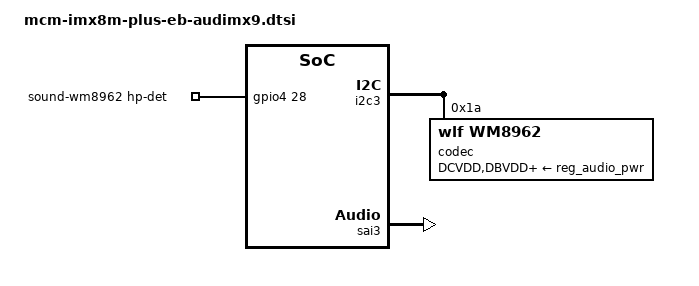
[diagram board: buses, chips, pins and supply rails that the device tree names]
&{/} {
	sound-wm8962 {
		compatible = "fsl,imx-audio-wm8962x";
		model = "wm8962-audio";
		audio-cpu = <&sai3>;
		audio-codec = <&codec>;
		hp-det-gpio = <&gpio4 28 0>;
		audio-routing =
			"Headphone Jack", "HPOUTL",
			"Headphone Jack", "HPOUTR",
			"Ext Spk", "SPKOUTL",
			"Ext Spk", "SPKOUTR",
			"AMIC", "MICBIAS",
			"IN1L", "AMIC",
			"IN1R", "AMIC";
	};
};

&i2c3 {
	#address-cells = <1>;
	#size-cells = <0>;
	status = "okay";

	codec: wm8962@1a {
		compatible = "wlf,wm8962";
		reg = <0x1a>;
		clocks = <&audio_blk_ctrl IMX8MP_CLK_AUDIOMIX_SAI3_MCLK1>;
		DCVDD-supply = <&reg_audio_pwr>;
		DBVDD-supply = <&reg_audio_pwr>;
		AVDD-supply = <&reg_audio_pwr>;
		CPVDD-supply = <&reg_audio_pwr>;
		MICVDD-supply = <&reg_audio_pwr>;
		PLLVDD-supply = <&reg_audio_pwr>;
		SPKVDD1-supply = <&reg_audio_pwr>;
		SPKVDD2-supply = <&reg_audio_pwr>;
		gpio-cfg = <
			0x0000 /* 0:Default */
			0x0000 /* 1:Default */
			0x0000 /* 2:FN_DMICCLK */
			0x0000 /* 3:Default */
			0x0000 /* 4:FN_DMICCDAT */
			0x0000 /* 5:Default */
		>;
		status = "okay";
	};
};

&sai3 {
	#sound-dai-cells = <0>;
	pinctrl-names = "default";
	pinctrl-0 = <&pinctrl_sai3>;
	assigned-clocks = <&clk IMX8MP_CLK_SAI3>;
	assigned-clock-parents = <&clk IMX8MP_AUDIO_PLL1_OUT>;
	assigned-clock-rates = <12288000>;
	clocks = <&audio_blk_ctrl IMX8MP_CLK_AUDIOMIX_SAI3_IPG>, <&clk IMX8MP_CLK_DUMMY>,
		 <&audio_blk_ctrl IMX8MP_CLK_AUDIOMIX_SAI3_MCLK1>, <&clk IMX8MP_CLK_DUMMY>,
		 <&clk IMX8MP_CLK_DUMMY>;
	clock-names = "bus", "mclk0", "mclk1", "mclk2", "mclk3";
	fsl,sai-mclk-direction-output;
	status = "okay";
};

&iomuxc {
	pinctrl_sai3: sai3grp {
		fsl,pins = <
			MX8MP_IOMUXC_SAI3_TXFS__AUDIOMIX_SAI3_TX_SYNC	0xd6
			MX8MP_IOMUXC_SAI3_TXC__AUDIOMIX_SAI3_TX_BCLK	0xd6
			MX8MP_IOMUXC_SAI3_RXD__AUDIOMIX_SAI3_RX_DATA00	0xd6
			MX8MP_IOMUXC_SAI3_TXD__AUDIOMIX_SAI3_TX_DATA00	0xd6
			MX8MP_IOMUXC_SAI3_MCLK__AUDIOMIX_SAI3_MCLK	0xd6
			MX8MP_IOMUXC_SAI3_RXFS__GPIO4_IO28		0xd6
		>;
	};
};
